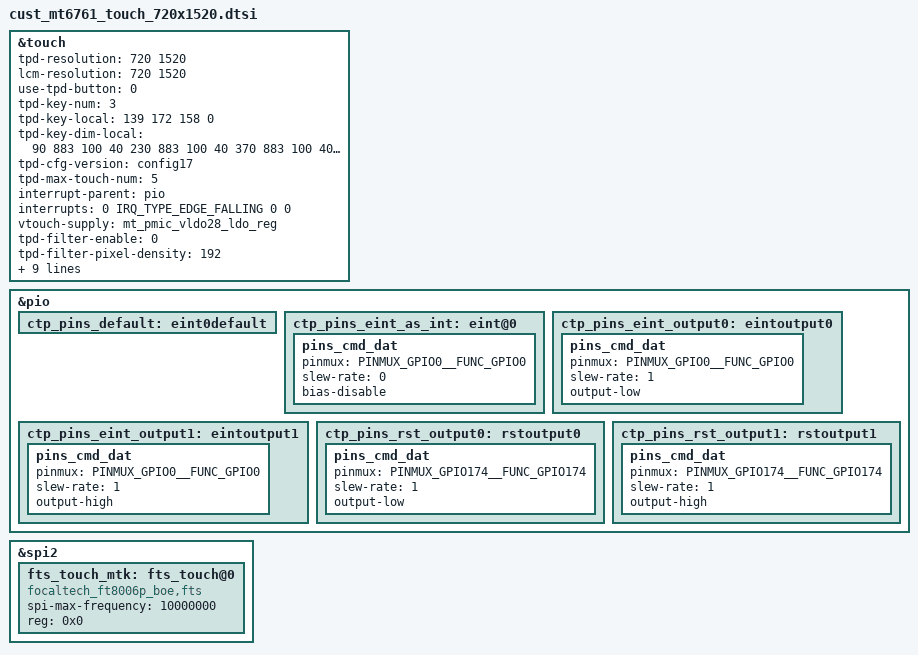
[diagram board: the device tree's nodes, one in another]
// SPDX-License-Identifier: GPL-2.0+
/*
 * Copyright (c) 2019 MediaTek Inc.
 *
 */

/* TOUCH start */
&touch {
	tpd-resolution = <720 1520>;
	lcm-resolution = <720 1520>;
	use-tpd-button = <0>;
	tpd-key-num = <3>;
	tpd-key-local= <139 172 158 0>;
	tpd-key-dim-local = <90 883 100 40 230
				 883 100 40 370 883 100 40 0 0 0 0>;
	tpd-cfg-version = "config17";
	tpd-max-touch-num = <5>;
	interrupt-parent = <&pio>;
	interrupts = <0 IRQ_TYPE_EDGE_FALLING 0 0>;

	vtouch-supply = <&mt_pmic_vldo28_ldo_reg>;
	tpd-filter-enable = <0>;
	tpd-filter-pixel-density = <192>;
	tpd-filter-custom-prameters = <0 0 0 0 0 0 0 0 0 0 0 0>;
	tpd-filter-custom-speed = <0 0 0>;
	pinctrl-names = "default", "state_eint_as_int", "state_eint_output0",
		"state_eint_output1", "state_rst_output0", "state_rst_output1";
	pinctrl-0 = <&ctp_pins_default>;
	pinctrl-1 = <&ctp_pins_eint_as_int>;
	pinctrl-2 = <&ctp_pins_eint_output0>;
	pinctrl-3 = <&ctp_pins_eint_output1>;
	pinctrl-4 = <&ctp_pins_rst_output0>;
	pinctrl-5 = <&ctp_pins_rst_output1>;
	status = "okay";
};
&pio {
	ctp_pins_default: eint0default {
	};
	ctp_pins_eint_as_int: eint@0 {
		pins_cmd_dat {
			pinmux = <PINMUX_GPIO0__FUNC_GPIO0>;
			slew-rate = <0>;
			bias-disable;
		};
	};
	ctp_pins_eint_output0: eintoutput0 {
		pins_cmd_dat {
			pinmux = <PINMUX_GPIO0__FUNC_GPIO0>;
			slew-rate = <1>;
			output-low;
		};
	};
	ctp_pins_eint_output1: eintoutput1 {
		pins_cmd_dat {
			pinmux = <PINMUX_GPIO0__FUNC_GPIO0>;
			slew-rate = <1>;
			output-high;
		};
	};
	ctp_pins_rst_output0: rstoutput0 {
		pins_cmd_dat {
			pinmux = <PINMUX_GPIO174__FUNC_GPIO174>;
			slew-rate = <1>;
			output-low;
		};
	};
	ctp_pins_rst_output1: rstoutput1 {
		pins_cmd_dat {
			pinmux = <PINMUX_GPIO174__FUNC_GPIO174>;
			slew-rate = <1>;
			output-high;
		};
	};
};
/* TOUCH end */

// touch
&spi2{
   #address-cells = <1>;
   #size-cells = <0>;
	fts_touch_mtk:fts_touch@0{
		compatible = "focaltech_ft8006p_boe,fts","focaltech_ft8615,fts","focaltech_ft8006p,fts","mediatek,himax_cap_touch","mediatek,ilitek_cap_touch";
                spi-max-frequency = <10000000>;
                reg = <0x0>;
                status = "okay";
        };
};
